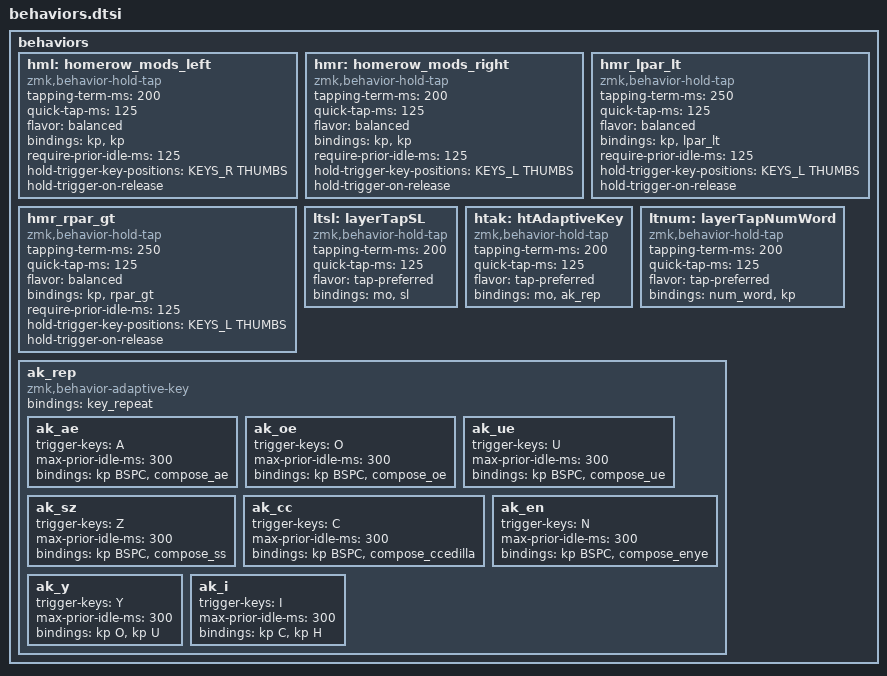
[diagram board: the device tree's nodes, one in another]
behaviors {
        // Homerow related behaviors
        hml: homerow_mods_left {
            compatible = "zmk,behavior-hold-tap";
            #binding-cells = <2>;
            tapping-term-ms = <200>;
            quick-tap-ms = <125>;
            flavor = "balanced";
            bindings = <&kp>, <&kp>;
            require-prior-idle-ms = <125>;
            hold-trigger-key-positions = <KEYS_R THUMBS>;
            hold-trigger-on-release;
        };
        hmr: homerow_mods_right {
            compatible = "zmk,behavior-hold-tap";
            #binding-cells = <2>;
            tapping-term-ms = <200>;
            quick-tap-ms = <125>;
            flavor = "balanced";
            bindings = <&kp>, <&kp>;
            require-prior-idle-ms = <125>;
            hold-trigger-key-positions = <KEYS_L THUMBS>;
            hold-trigger-on-release;
        };
        hmr_lpar_lt: hmr_lpar_lt {
            compatible = "zmk,behavior-hold-tap";
            #binding-cells = <2>;
            tapping-term-ms = <250>;
            quick-tap-ms = <125>;
            flavor = "balanced";
            bindings = <&kp>, <&lpar_lt>;
            require-prior-idle-ms = <125>;
            hold-trigger-key-positions = <KEYS_L THUMBS>;
            hold-trigger-on-release;
        };
        hmr_rpar_gt: hmr_rpar_gt {
            compatible = "zmk,behavior-hold-tap";
            #binding-cells = <2>;
            tapping-term-ms = <250>;
            quick-tap-ms = <125>;
            flavor = "balanced";
            bindings = <&kp>, <&rpar_gt>;
            require-prior-idle-ms = <125>;
            hold-trigger-key-positions = <KEYS_L THUMBS>;
            hold-trigger-on-release;
        };

        // Layer switching related behaviors
        ltsl: layerTapSL {
            compatible = "zmk,behavior-hold-tap";
            #binding-cells = <2>;
            tapping-term-ms = <200>;
            quick-tap-ms = <125>;
            flavor = "tap-preferred";
            bindings =
                <&mo>,
                <&sl>;
        };

        htak: htAdaptiveKey { 
            // Used for repead key or adaptive key
            compatible = "zmk,behavior-hold-tap";
            #binding-cells = <2>;
            tapping-term-ms = <200>;
            quick-tap-ms = <125>;
            flavor = "tap-preferred";
            bindings =
                <&mo>,
                <&ak_rep>;
        };
        
        ltnum: layerTapNumWord {
            compatible = "zmk,behavior-hold-tap";
            #binding-cells = <2>;
            tapping-term-ms = <200>;
            quick-tap-ms = <125>;
            flavor = "tap-preferred";
            bindings =
                <&num_word>,
                <&kp>;
        };
        //

        // Adaptive Key related behaviors
        ak_rep: ak_rep {
            // Repeat key or umlaut
            compatible = "zmk,behavior-adaptive-key";
            #binding-cells = <0>;
            bindings = <&key_repeat>;
            ak_ae { trigger-keys = <A>; max-prior-idle-ms = <300>; bindings = <&kp BSPC>,<&compose_ae>;};
            ak_oe { trigger-keys = <O>; max-prior-idle-ms = <300>; bindings = <&kp BSPC>,<&compose_oe>;};
            ak_ue { trigger-keys = <U>; max-prior-idle-ms = <300>; bindings = <&kp BSPC>,<&compose_ue>;};
            ak_sz { trigger-keys = <Z>; max-prior-idle-ms = <300>; bindings = <&kp BSPC>,<&compose_ss>;};
            ak_cc { trigger-keys = <C>; max-prior-idle-ms = <300>; bindings = <&kp BSPC>,<&compose_ccedilla>;};
            ak_en { trigger-keys = <N>; max-prior-idle-ms = <300>; bindings = <&kp BSPC>,<&compose_enye>;};
            ak_y  { trigger-keys = <Y>; max-prior-idle-ms = <300>; bindings = <&kp O>,<&kp U>;};
            ak_i  { trigger-keys = <I>; max-prior-idle-ms = <300>; bindings = <&kp C>,<&kp H>;};
    
            /* ak_ae { trigger-keys = <A>; max-prior-idle-ms = <300>; bindings = <&kp BSPC>,<&uc UC_DE_AE>;}; */
            /* ak_oe { trigger-keys = <O>; max-prior-idle-ms = <300>; bindings = <&kp BSPC>,<&uc UC_DE_OE>;}; */
            /* ak_ue { trigger-keys = <U>; max-prior-idle-ms = <300>; bindings = <&kp BSPC>,<&uc UC_DE_UE>;}; */
            /* ak_sz { trigger-keys = <Z>; max-prior-idle-ms = <300>; bindings = <&kp BSPC>,<&uc UC_DE_SS>;}; */
            /* ak_y  { trigger-keys = <Y>; max-prior-idle-ms = <300>; bindings = <&kp O>,<&kp U>;}; */
            /* ak_i  { trigger-keys = <I>; max-prior-idle-ms = <300>; bindings = <&kp C>,<&kp H>;}; */
        };

    };
    
